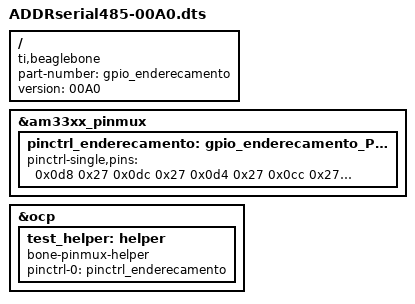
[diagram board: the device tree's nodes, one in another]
/dts-v1/;
/plugin/;

/{

	compatible = "ti,beaglebone", "ti,beaglebone-black";
	part-number = "gpio_enderecamento";
	version = "00A0";

	fragment@0 {
		target = <&am33xx_pinmux>;
		__overlay__ {
			pinctrl_enderecamento: gpio_enderecamento_Pins {
				pinctrl-single,pins = <
					0x0d8 0x27 /* P8_31 60 */
					0x0dc 0x27 /* P8_32 15 */
					0x0d4 0x27 /* P8_33 45 */
					0x0cc 0x27 /* P8_34 44 INPUT MODE7 pulldown */
					0x0d0 0x27 /* P8_35 23 */
				>;
			};
		};
	};


	fragment@1 {
		target = <&ocp>;
		__overlay__ {
			test_helper: helper {
				compatible = "bone-pinmux-helper";
				pinctrl-names = "default";
				pinctrl-0 = <&pinctrl_enderecamento>;
				status = "okay";
			};
		};
	};
};




